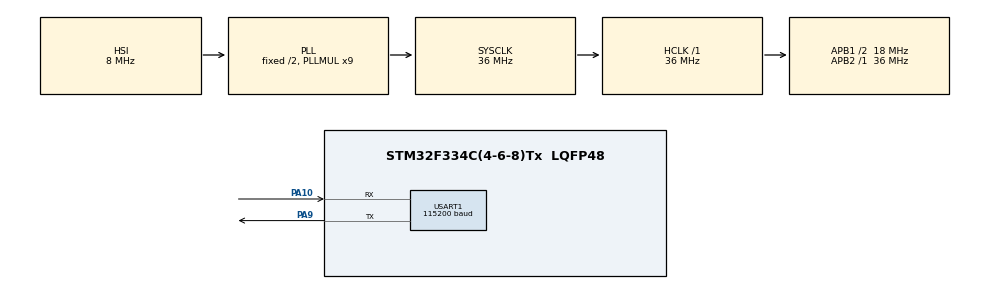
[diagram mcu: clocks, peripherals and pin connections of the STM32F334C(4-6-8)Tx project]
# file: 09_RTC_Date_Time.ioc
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Mcu.Family=STM32F3
Mcu.Name=STM32F334C(4-6-8)Tx
Mcu.Package=LQFP48
NVIC.PriorityGroup=NVIC_PRIORITYGROUP_0
PA10.Mode=Asynchronous
PA10.Signal=USART1_RX
PA9.Mode=Asynchronous
PA9.Signal=USART1_TX
ProjectManager.HeapSize=0x200
ProjectManager.StackSize=0x400
ProjectManager.TargetToolchain=STM32CubeIDE
RCC.AHBFreq_Value=36000000
RCC.APB1CLKDivider=RCC_HCLK_DIV2
RCC.APB1Freq_Value=18000000
RCC.APB1TimFreq_Value=36000000
RCC.APB2Freq_Value=36000000
RCC.APB2TimFreq_Value=36000000
RCC.CortexFreq_Value=36000000
RCC.HCLKFreq_Value=36000000
RCC.HSE_VALUE=8000000
RCC.HSI_VALUE=8000000
RCC.LSE_VALUE=32768
RCC.PLLMUL=RCC_PLL_MUL9
RCC.SYSCLKFreq_VALUE=36000000
RCC.SYSCLKSourceVirtual=RCC_SYSCLKSOURCE_PLLCLK
RTC.Date=26
RTC.Format=RTC_FORMAT_BCD
RTC.HourFormat=RTC_HOURFORMAT_12
RTC.Hours=12
RTC.Minutes=15
RTC.Month=RTC_MONTH_OCTOBER
RTC.TimeFormat=RTC_HOURFORMAT12_PM
RTC.WeekDay=RTC_WEEKDAY_THURSDAY
RTC.Year=23
USART1.BaudRate=115200
USART1.VirtualMode-Asynchronous=VM_ASYNC
VP_RTC_VS_RTC_Activate.Mode=RTC_Enabled
VP_RTC_VS_RTC_Calendar.Mode=RTC_Calendar
board=STM32F3348-DISCO

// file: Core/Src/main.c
/* USER CODE BEGIN Header */
/**
 ******************************************************************************
 * @file           : main.c
 * @brief          : Main program body
 ******************************************************************************
 * @attention
 *
 * Copyright (c) 2023 STMicroelectronics.
 * All rights reserved.
 *
 * This software is licensed under terms that can be found in the LICENSE file
 * in the root directory of this software component.
 * If no LICENSE file comes with this software, it is provided AS-IS.
 *
 ******************************************************************************
 */
/* USER CODE END Header */
#include "main.h"

/* USER CODE BEGIN Includes */
#include <stdio.h>
#include <string.h>
#include <stdlib.h>
/* USER CODE END Includes */

/* USER CODE BEGIN PTD */
RTC_TimeTypeDef sTime ={0};
RTC_DateTypeDef sDate ={0};
/* USER CODE END PTD */

RTC_HandleTypeDef hrtc;

UART_HandleTypeDef huart1;

/* USER CODE BEGIN PV */
char time_date[60];
/* USER CODE END PV */

void SystemClock_Config(void);
static void MX_GPIO_Init(void);
static void MX_RTC_Init(void);
static void MX_USART1_UART_Init(void);

int main(void) {

	/* MCU Configuration--------------------------------------------------------*/

	/* Reset of all peripherals, Initializes the Flash interface and the Systick. */
	HAL_Init();

	/* Configure the system clock */
	SystemClock_Config();

	/* Initialize all configured peripherals */
	MX_GPIO_Init();
	MX_RTC_Init();
	MX_USART1_UART_Init();

	/* Infinite loop */
	/* USER CODE BEGIN WHILE */
	while (1) {
		  HAL_RTC_GetDate(&hrtc, &sDate, RTC_FORMAT_BIN);
		  HAL_RTC_GetTime(&hrtc, &sTime, RTC_FORMAT_BIN);

		  sprintf(time_date,"%02d.%02d.%02d and %02d.%02d.%02d\r\n",sTime.Hours,sTime.Minutes,sTime.Seconds,sDate.Date,sDate.Month,sDate.Year);
		  HAL_UART_Transmit(&huart1, (uint8_t*)time_date, strlen(time_date), HAL_MAX_DELAY);
		  HAL_Delay(1000);
		/* USER CODE END WHILE */

	}
}

void SystemClock_Config(void) {
	RCC_OscInitTypeDef RCC_OscInitStruct = { 0 };
	RCC_ClkInitTypeDef RCC_ClkInitStruct = { 0 };
	RCC_PeriphCLKInitTypeDef PeriphClkInit = { 0 };

	/** Initializes the RCC Oscillators according to the specified parameters
	 * in the RCC_OscInitTypeDef structure.
	 */
	RCC_OscInitStruct.OscillatorType = RCC_OSCILLATORTYPE_HSI
			| RCC_OSCILLATORTYPE_LSI;
	RCC_OscInitStruct.HSIState = RCC_HSI_ON;
	RCC_OscInitStruct.HSICalibrationValue = RCC_HSICALIBRATION_DEFAULT;
	RCC_OscInitStruct.LSIState = RCC_LSI_ON;
	RCC_OscInitStruct.PLL.PLLState = RCC_PLL_ON;
	RCC_OscInitStruct.PLL.PLLSource = RCC_PLLSOURCE_HSI;
	RCC_OscInitStruct.PLL.PLLMUL = RCC_PLL_MUL9;
	if (HAL_RCC_OscConfig(&RCC_OscInitStruct) != HAL_OK) {
		Error_Handler();
	}

	/** Initializes the CPU, AHB and APB buses clocks
	 */
	RCC_ClkInitStruct.ClockType = RCC_CLOCKTYPE_HCLK | RCC_CLOCKTYPE_SYSCLK
			| RCC_CLOCKTYPE_PCLK1 | RCC_CLOCKTYPE_PCLK2;
	RCC_ClkInitStruct.SYSCLKSource = RCC_SYSCLKSOURCE_PLLCLK;
	RCC_ClkInitStruct.AHBCLKDivider = RCC_SYSCLK_DIV1;
	RCC_ClkInitStruct.APB1CLKDivider = RCC_HCLK_DIV2;
	RCC_ClkInitStruct.APB2CLKDivider = RCC_HCLK_DIV1;

	if (HAL_RCC_ClockConfig(&RCC_ClkInitStruct, FLASH_LATENCY_1) != HAL_OK) {
		Error_Handler();
	}
	PeriphClkInit.PeriphClockSelection = RCC_PERIPHCLK_USART1
			| RCC_PERIPHCLK_RTC;
	PeriphClkInit.Usart1ClockSelection = RCC_USART1CLKSOURCE_PCLK1;
	PeriphClkInit.RTCClockSelection = RCC_RTCCLKSOURCE_LSI;
	if (HAL_RCCEx_PeriphCLKConfig(&PeriphClkInit) != HAL_OK) {
		Error_Handler();
	}
}

static void MX_RTC_Init(void) {

	RTC_TimeTypeDef sTime = { 0 };
	RTC_DateTypeDef sDate = { 0 };

	/** Initialize RTC Only
	 */
	hrtc.Instance = RTC;
	hrtc.Init.HourFormat = RTC_HOURFORMAT_12;
	hrtc.Init.AsynchPrediv = 127;
	hrtc.Init.SynchPrediv = 255;
	hrtc.Init.OutPut = RTC_OUTPUT_DISABLE;
	hrtc.Init.OutPutPolarity = RTC_OUTPUT_POLARITY_HIGH;
	hrtc.Init.OutPutType = RTC_OUTPUT_TYPE_OPENDRAIN;
	if (HAL_RTC_Init(&hrtc) != HAL_OK) {
		Error_Handler();
	}

	/** Initialize RTC and set the Time and Date
	 */
	sTime.Hours = 0x12;
	sTime.Minutes = 0x15;
	sTime.Seconds = 0x0;
	sTime.TimeFormat = RTC_HOURFORMAT12_PM;
	sTime.DayLightSaving = RTC_DAYLIGHTSAVING_NONE;
	sTime.StoreOperation = RTC_STOREOPERATION_RESET;
	if (HAL_RTC_SetTime(&hrtc, &sTime, RTC_FORMAT_BCD) != HAL_OK) {
		Error_Handler();
	}
	sDate.WeekDay = RTC_WEEKDAY_THURSDAY;
	sDate.Month = RTC_MONTH_OCTOBER;
	sDate.Date = 0x26;
	sDate.Year = 0x23;

	if (HAL_RTC_SetDate(&hrtc, &sDate, RTC_FORMAT_BCD) != HAL_OK) {
		Error_Handler();
	}
	/* USER CODE BEGIN RTC_Init 2 */
//	HAL_RTCEx_BKUPWrite(&hrtc, RTC_BKP_DR1, 0x32F2);
	/* USER CODE END RTC_Init 2 */

}

static void MX_USART1_UART_Init(void) {

	huart1.Instance = USART1;
	huart1.Init.BaudRate = 115200;
	huart1.Init.WordLength = UART_WORDLENGTH_8B;
	huart1.Init.StopBits = UART_STOPBITS_1;
	huart1.Init.Parity = UART_PARITY_NONE;
	huart1.Init.Mode = UART_MODE_TX_RX;
	huart1.Init.HwFlowCtl = UART_HWCONTROL_NONE;
	huart1.Init.OverSampling = UART_OVERSAMPLING_16;
	huart1.Init.OneBitSampling = UART_ONE_BIT_SAMPLE_DISABLE;
	huart1.AdvancedInit.AdvFeatureInit = UART_ADVFEATURE_NO_INIT;
	if (HAL_UART_Init(&huart1) != HAL_OK) {
		Error_Handler();
	}

}

static void MX_GPIO_Init(void) {

	/* GPIO Ports Clock Enable */
	__HAL_RCC_GPIOA_CLK_ENABLE();

}

void Error_Handler(void) {
	__disable_irq();
	while (1) {
	}
}
